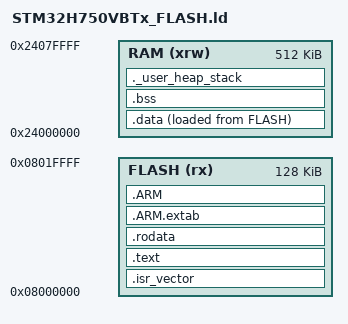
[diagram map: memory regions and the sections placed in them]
/* STM32H750VBT6 链接脚本
 * Flash : 0x08000000, 128 KB（H750 只有这一个扇区，擦除会连代码一起擦，
 *         因此本工程不把参数放内部 Flash —— 见 docs/bringup.md §4）
 * RAM   : 0x24000000, 512 KB AXI SRAM（DTCM 另在 0x20000000，本工程未用）
 */
ENTRY(Reset_Handler)

MEMORY
{
  FLASH (rx)  : ORIGIN = 0x08000000, LENGTH = 128K
  RAM   (xrw) : ORIGIN = 0x24000000, LENGTH = 512K
}

_estack = ORIGIN(RAM) + LENGTH(RAM);
_min_stack_size = 0x4000;   /* 16 KB 栈，够 HAL + 浮点运算 */

SECTIONS
{
  .isr_vector :
  {
    . = ALIGN(4);
    KEEP(*(.isr_vector))
    . = ALIGN(4);
  } > FLASH

  .text :
  {
    . = ALIGN(4);
    *(.text)
    *(.text*)
    *(.glue_7)
    *(.glue_7t)
    *(.eh_frame)
    KEEP(*(.init))
    KEEP(*(.fini))
    . = ALIGN(4);
    _etext = .;
  } > FLASH

  .rodata :
  {
    . = ALIGN(4);
    *(.rodata)
    *(.rodata*)
    . = ALIGN(4);
  } > FLASH

  .ARM.extab :
  {
    *(.ARM.extab* .gnu.linkonce.armextab.*)
  } > FLASH

  .ARM :
  {
    __exidx_start = .;
    *(.ARM.exidx*)
    __exidx_end = .;
  } > FLASH

  _sidata = LOADADDR(.data);

  .data :
  {
    . = ALIGN(4);
    _sdata = .;
    *(.data)
    *(.data*)
    . = ALIGN(4);
    _edata = .;
  } > RAM AT> FLASH

  .bss :
  {
    . = ALIGN(4);
    _sbss = .;
    __bss_start__ = _sbss;
    *(.bss)
    *(.bss*)
    *(COMMON)
    . = ALIGN(4);
    _ebss = .;
    __bss_end__ = _ebss;
  } > RAM

  ._user_heap_stack :
  {
    . = ALIGN(8);
    PROVIDE(end = .);
    PROVIDE(_end = .);
    . = . + _min_stack_size;
    . = ALIGN(8);
  } > RAM

  .ARM.attributes 0 : { *(.ARM.attributes) }
}
